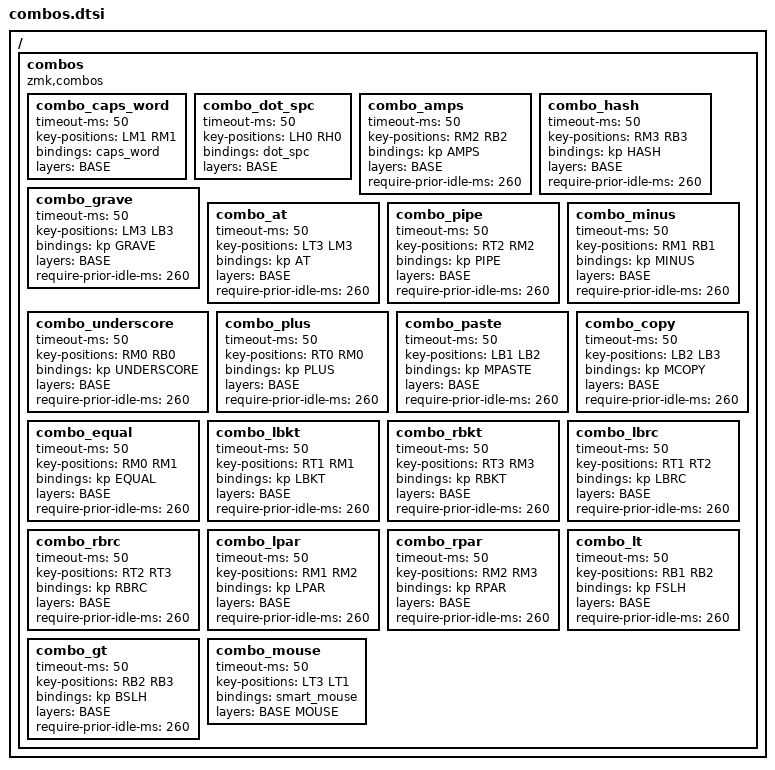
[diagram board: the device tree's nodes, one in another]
/*                KEY POSITIONS

  ╭─────────────────────╮ ╭─────────────────────╮
  │ LT4 LT3 LT2 LT1 LT0 │ │ RT0 RT1 RT2 RT3 RT4 │
  │ LM4 LM3 LM2 LM1 LM0 │ │ RM0 RM1 RM2 RM3 RM4 │
  │ LB4 LB3 LB2 LB1 LB0 │ │ RB0 RB1 RB2 RB3 RB4 │
  ╰───────╮ LH2 LH1 LH0 │ │ RH0 RH1 RH2 ╭───────╯
          ╰─────────────╯ ╰─────────────╯ */

#define MCOPY LG(C)
#define MPASTE LG(V)

/ {
  // idle timeout for combos is 10500/40 = 260
  combos {
    compatible = "zmk,combos";

    combo_caps_word {
      timeout-ms = <50>;
      key-positions = <LM1 RM1>;
      bindings = <&caps_word>;
      layers = <BASE>;
    };

    combo_dot_spc {
      timeout-ms = <50>;
      key-positions = <LH0 RH0>;
      bindings = <&dot_spc>;
      layers = <BASE>;
    };

    combo_amps {
      timeout-ms = <50>;
      key-positions = <RM2 RB2>;
      bindings = <&kp AMPS>;
      layers = <BASE>;
      require-prior-idle-ms = <260>;
    };

    combo_hash {
      timeout-ms = <50>;
      key-positions = <RM3 RB3>;
      bindings = <&kp HASH>;
      layers = <BASE>;
      require-prior-idle-ms = <260>;
    };

    combo_grave {
      timeout-ms = <50>;
      key-positions = <LM3 LB3>;
      bindings = <&kp GRAVE>;
      layers = <BASE>;
      require-prior-idle-ms = <260>;
    };

    combo_at {
      timeout-ms = <50>;
      key-positions = <LT3 LM3>;
      bindings = <&kp AT>;
      layers = <BASE>;
      require-prior-idle-ms = <260>;
    };

    combo_pipe {
      timeout-ms = <50>;
      key-positions = <RT2 RM2>;
      bindings = <&kp PIPE>;
      layers = <BASE>;
      require-prior-idle-ms = <260>;
    };

    combo_minus {
      timeout-ms = <50>;
      key-positions = <RM1 RB1>;
      bindings = <&kp MINUS>;
      layers = <BASE>;
      require-prior-idle-ms = <260>;
    };

    combo_underscore {
      timeout-ms = <50>;
      key-positions = <RM0 RB0>;
      bindings = <&kp UNDERSCORE>;
      layers = <BASE>;
      require-prior-idle-ms = <260>;
    };

    combo_plus {
      timeout-ms = <50>;
      key-positions = <RT0 RM0>;
      bindings = <&kp PLUS>;
      layers = <BASE>;
      require-prior-idle-ms = <260>;
    };

    combo_paste {
      timeout-ms = <50>;
      key-positions = <LB1 LB2>;
      bindings = <&kp MPASTE>;
      layers = <BASE>;
      require-prior-idle-ms = <260>;
    };

    combo_copy {
      timeout-ms = <50>;
      key-positions = <LB2 LB3>;
      bindings = <&kp MCOPY>;
      layers = <BASE>;
      require-prior-idle-ms = <260>;
    };

    combo_equal {
      timeout-ms = <50>;
      key-positions = <RM0 RM1>;
      bindings = <&kp EQUAL>;
      layers = <BASE>;
      require-prior-idle-ms = <260>;
    };

    // [
    combo_lbkt {
      timeout-ms = <50>;
      key-positions = <RT1 RM1>;
      bindings = <&kp LBKT>;
      layers = <BASE>;
      require-prior-idle-ms = <260>;
    };

    // ]
    combo_rbkt {
      timeout-ms = <50>;
      key-positions = <RT3 RM3>;
      bindings = <&kp RBKT>;
      layers = <BASE>;
      require-prior-idle-ms = <260>;
    };

    // {
    combo_lbrc {
      timeout-ms = <50>;
      key-positions = <RT1 RT2>;
      bindings = <&kp LBRC>;
      layers = <BASE>;
      require-prior-idle-ms = <260>;
    };

    // }
    combo_rbrc {
      timeout-ms = <50>;
      key-positions = <RT2 RT3>;
      bindings = <&kp RBRC>;
      layers = <BASE>;
      require-prior-idle-ms = <260>;
    };

    // (
    combo_lpar {
      timeout-ms = <50>;
      key-positions = <RM1 RM2>;
      bindings = <&kp LPAR>;
      layers = <BASE>;
      require-prior-idle-ms = <260>;
    };

    // )
    combo_rpar {
      timeout-ms = <50>;
      key-positions = <RM2 RM3>;
      bindings = <&kp RPAR>;
      layers = <BASE>;
      require-prior-idle-ms = <260>;
    };

    // <
    combo_lt {
      timeout-ms = <50>;
      key-positions = <RB1 RB2>;
      bindings = <&kp FSLH>;
      layers = <BASE>;
      require-prior-idle-ms = <260>;
    };

    // >
    combo_gt {
      timeout-ms = <50>;
      key-positions = <RB2 RB3>;
      bindings = <&kp BSLH>;
      layers = <BASE>;
      require-prior-idle-ms = <260>;
    };

    // mouse
    combo_mouse {
      timeout-ms = <50>;
      key-positions = <LT3 LT1>;
      bindings = <&smart_mouse>;
      layers = <BASE MOUSE>;
    };
  };
};
